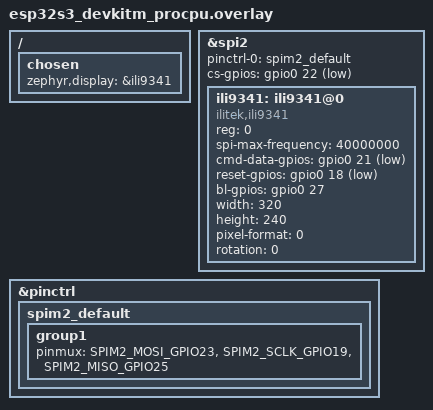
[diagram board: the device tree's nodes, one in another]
/*
 * Copyright (c) 2025 Artur Wiebe (ArturR0k3r)
 * SPDX-License-Identifier: Apache-2.0
 */

/ {
	chosen {
		zephyr,display = &ili9341;
	};
};

&spi2 {
	status = "okay";
	pinctrl-0 = <&spim2_default>;
	pinctrl-names = "default";
	cs-gpios = <&gpio0 22 GPIO_ACTIVE_LOW>;
	
	ili9341: ili9341@0 {
		compatible = "ilitek,ili9341";
		reg = <0>;
		spi-max-frequency = <40000000>;
		cmd-data-gpios = <&gpio0 21 GPIO_ACTIVE_LOW>;
		reset-gpios = <&gpio0 18 GPIO_ACTIVE_LOW>;
		bl-gpios = <&gpio0 27 GPIO_ACTIVE_HIGH>;
		width = <320>;
		height = <240>;
		pixel-format = <0>; /* RGB565 */
		rotation = <0>;
		/* Proven initialization sequence from AkiraOS */
		/* These values work reliably across many ILI9341 modules */
	};
};

&pinctrl {
	spim2_default: spim2_default {
		group1 {
			pinmux = <SPIM2_MOSI_GPIO23>,
				 <SPIM2_SCLK_GPIO19>,
				 <SPIM2_MISO_GPIO25>;
		};
	};
};
